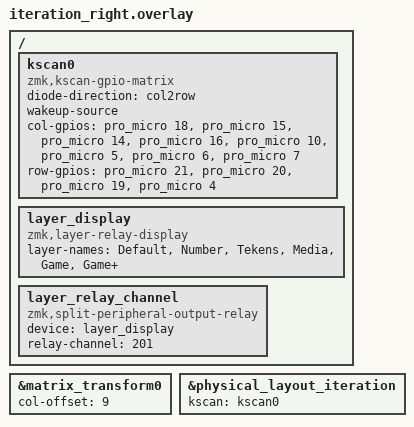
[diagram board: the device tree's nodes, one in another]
#include "iteration.dtsi"

/ {
    kscan0: kscan0 {
        compatible = "zmk,kscan-gpio-matrix";
        diode-direction = "col2row";
        wakeup-source;

        col-gpios
            = <&pro_micro 18 GPIO_ACTIVE_HIGH>
            , <&pro_micro 15 GPIO_ACTIVE_HIGH>
            , <&pro_micro 14 GPIO_ACTIVE_HIGH>
            , <&pro_micro 16 GPIO_ACTIVE_HIGH>
            , <&pro_micro 10 GPIO_ACTIVE_HIGH>
            , <&pro_micro 5 GPIO_ACTIVE_HIGH>
            , <&pro_micro 6 GPIO_ACTIVE_HIGH>
            , <&pro_micro 7 GPIO_ACTIVE_HIGH>
            ;

        row-gpios
            = <&pro_micro 21 (GPIO_ACTIVE_HIGH | GPIO_PULL_DOWN)>
            , <&pro_micro 20 (GPIO_ACTIVE_HIGH | GPIO_PULL_DOWN)>
            , <&pro_micro 19 (GPIO_ACTIVE_HIGH | GPIO_PULL_DOWN)>
            , <&pro_micro 4 (GPIO_ACTIVE_HIGH | GPIO_PULL_DOWN)>
            ;
    };
};

&matrix_transform0 {
    col-offset = <9>;
};

&physical_layout_iteration {
    kscan = <&kscan0>;
};


/* Layer relay (peripheral side): receive the layer and show it on the nice!view */
/ {
    layer_display: layer_display {
        compatible = "zmk,layer-relay-display";
        layer-names = "Default", "Number", "Tekens", "Media", "Game", "Game+";
    };

    layer_relay_channel {
        compatible = "zmk,split-peripheral-output-relay";
        device = <&layer_display>;
        relay-channel = <201>;
    };
};
